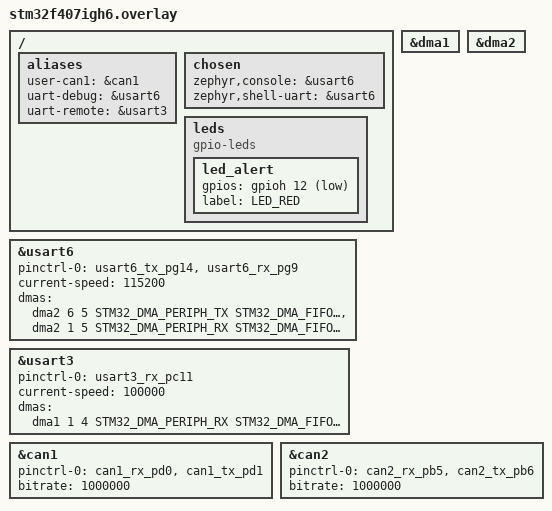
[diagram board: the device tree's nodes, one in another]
#include <dt-bindings/gpio/gpio.h>

/ {
	aliases {
		user-can1 = &can1;
		uart-debug = &usart6;
		uart-remote = &usart3;
	};
	chosen {
		zephyr,console = &usart6;
		zephyr,shell-uart = &usart6;
	};
	leds {
		compatible = "gpio-leds";
		led_alert: led_alert {
			gpios = <&gpioh 12 GPIO_ACTIVE_LOW>;
			label = "LED_RED";
		};
	};
};

&usart6 {
	pinctrl-0 = <&usart6_tx_pg14 &usart6_rx_pg9>;
	pinctrl-names = "default";
	current-speed = <115200>;
	dmas = <&dma2 6 5 STM32_DMA_PERIPH_TX STM32_DMA_FIFO_FULL>,
	       <&dma2 1 5 STM32_DMA_PERIPH_RX STM32_DMA_FIFO_FULL>;
	dma-names = "tx", "rx";
	status = "okay";
};

&usart3 {
	pinctrl-0 = <&usart3_rx_pc11>;
	pinctrl-names = "default";
	current-speed = <100000>;
	dmas = <&dma1 1 4 STM32_DMA_PERIPH_RX STM32_DMA_FIFO_FULL>;
	dma-names = "rx";
	status = "okay";
};

&dma1 {
	status = "okay";
};

&dma2 {
	status = "okay";
};

&can1 {
	pinctrl-0 = <&can1_rx_pd0 &can1_tx_pd1>;
	pinctrl-names = "default";
	bitrate = <1000000>;
	status = "okay";
};

&can2 {
	pinctrl-0 = <&can2_rx_pb5 &can2_tx_pb6>;
	pinctrl-names = "default";
	bitrate = <1000000>;
	status = "okay";
};


